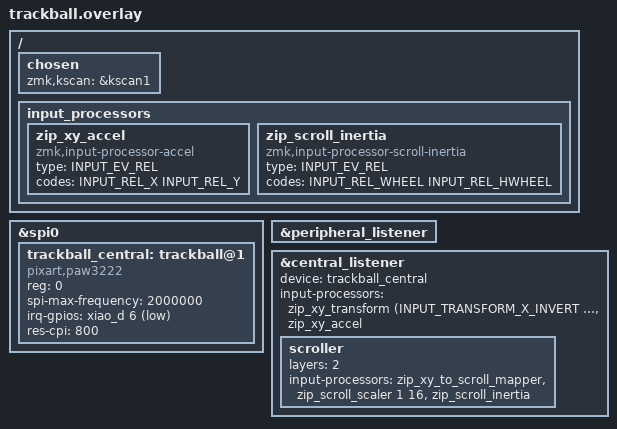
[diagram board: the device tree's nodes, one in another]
/ {
    chosen {
        zmk,kscan = &kscan1;
    };

    input_processors {
        zip_xy_accel: zip_xy_accel {
            compatible = "zmk,input-processor-accel";
            #input-processor-cells = <0>;
            type = <INPUT_EV_REL>;
            codes = <INPUT_REL_X INPUT_REL_Y>;
        };

        zip_scroll_inertia: zip_scroll_inertia {
            compatible = "zmk,input-processor-scroll-inertia";
            #input-processor-cells = <0>;
            type = <INPUT_EV_REL>;
            codes = <INPUT_REL_WHEEL INPUT_REL_HWHEEL>;
        };
    };
};

&spi0 {
    status = "okay";

    trackball_central: trackball@1 {
        status = "okay";
        compatible = "pixart,paw3222";
        reg = <0>;
        spi-max-frequency = <2000000>;
        irq-gpios = <&xiao_d 6 (GPIO_ACTIVE_LOW | GPIO_PULL_UP)>;
        res-cpi = <800>;
        // force-awake;
    };
};

// ペリフェラル（split経由）のリスナーを有効化
&peripheral_listener {
    status = "okay";
};

// セントラルのリスナーを有効化し、deviceを紐付け
&central_listener {
    status = "okay";
    device = <&trackball_central>;
    input-processors =
        <&zip_xy_transform (INPUT_TRANSFORM_X_INVERT | INPUT_TRANSFORM_Y_INVERT)>,
        <&zip_xy_accel>;

    scroller {
        layers = <2>;
        input-processors =
            <&zip_xy_to_scroll_mapper>,
            <&zip_scroll_scaler 1 16>,
            <&zip_scroll_inertia>;
    };
};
